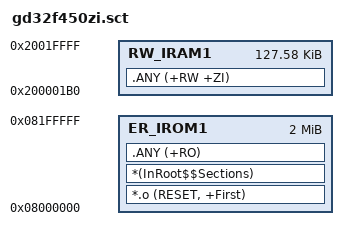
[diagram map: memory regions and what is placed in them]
#! armcc -E
; *************************************************************
; *** Scatter-Loading Description File generated by uVision ***
; *****

#if !defined(MBED_APP_START)
  #define MBED_APP_START 0x08000000
#endif

#if !defined(MBED_APP_SIZE)
  #define MBED_APP_SIZE 0x200000
#endif

LR_IROM1 MBED_APP_START MBED_APP_SIZE  {    ; load region size_region (3*1024K)

  ER_IROM1 MBED_APP_START MBED_APP_SIZE  {  ; load address = execution address
   *.o (RESET, +First)
   *(InRoot$$Sections)
   .ANY (+RO)
  }

  ; 107 vectors (16 core + 91 peripheral) * 4 bytes = 428 bytes to reserve (0x1B0, 8-byte aligned)
  RW_IRAM1 (0x20000000+0x1B0) (0x20000-0x1B0)  {  ; RW data
   .ANY (+RW +ZI)
  }
}
